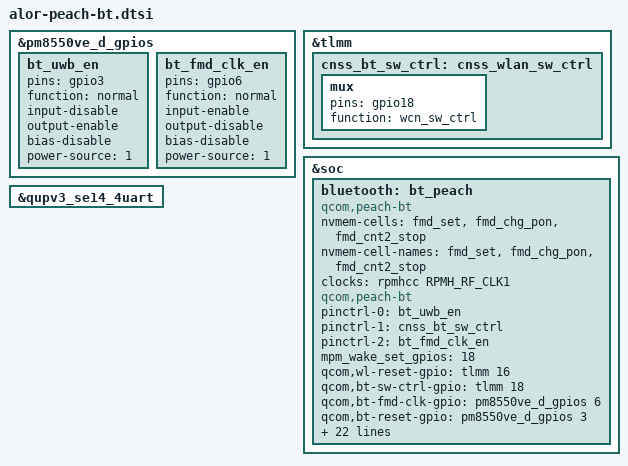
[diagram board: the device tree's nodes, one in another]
// SPDX-License-Identifier: BSD-3-Clause-Clear 
/*
 * Copyright (c) Qualcomm Technologies, Inc. and/or its subsidiaries.
 */

#include <dt-bindings/interconnect/qcom,alor.h>
#include <dt-bindings/clock/qcom,rpmh.h>

&pm8550ve_d_gpios {
	bt_uwb_en: bt_uwb_en {
		pins = "gpio3";
		function = "normal";
		input-disable;
		output-enable;
		bias-disable;
		power-source = <1>;
	};
	bt_fmd_clk_en: bt_fmd_clk_en {
		pins = "gpio6";
		function = "normal";
		input-enable;
		output-disable;
		bias-disable;
		power-source = <1>;
	};
};

&tlmm {
	cnss_bt_sw_ctrl: cnss_wlan_sw_ctrl {
		mux {
			pins = "gpio18";
			function = "wcn_sw_ctrl";
		};
	};
};

&soc {
	bluetooth: bt_peach {
		compatible = "qcom,peach-bt";
		nvmem-cells = <&fmd_set>, <&fmd_chg_pon>, <&fmd_cnt2_stop>;
		nvmem-cell-names = "fmd_set", "fmd_chg_pon", "fmd_cnt2_stop";
		clocks = <&rpmhcc RPMH_RF_CLK1>;
		clock-names = "bt_rf_clk1";
		qcom,peach-bt;
		pinctrl-names = "bt_uwb_en", "sw_ctrl", "bt_fmd_clk_en";
		pinctrl-0 = <&bt_uwb_en>;
		pinctrl-1 = <&cnss_bt_sw_ctrl>;
		pinctrl-2 = <&bt_fmd_clk_en>;
		/* List of GPIOs to be setup for interrupt wakeup capable*/
		mpm_wake_set_gpios = <18>;
		qcom,wl-reset-gpio = <&tlmm 16 0>; /* WL_EN */
		qcom,bt-sw-ctrl-gpio = <&tlmm 18 0>; /* SW_CTRL */
		qcom,bt-fmd-clk-gpio = <&pm8550ve_d_gpios 6 0>; /* FMD_CLK_CTRL */
		qcom,bt-reset-gpio = <&pm8550ve_d_gpios 3 0>; /* BT_EN */
		qcom,qmp = <&aoss_qmp>;

		qcom,bt-vdd18-aon-supply  = <&L2D>;   /* VDD1P8_AON */
		qcom,bt-vdd12-io-supply   = <&L3D>;   /* VDD1P2_IO */
		qcom,bt-ant-ldo-supply    = <&L6K>;   /* AV91C_VDD Extractor */
		qcom,bt-vdd-dig-supply    = <&S1L>;   /* BT CX_MX LDO */
		qcom,bt-vdd-aon-supply    = <&S1L>;   /* RFA_CMN/AON */
		qcom,bt-vdd-rfa0p75-supply = <&S1J>;  /* RFA_OP75 */
		qcom,bt-vdd-rfa1p8-supply  = <&S4D>;  /* RFA_1P8 */
		qcom,bt-vdd-rfa1p25-supply = <&S4F>; /* RFA_1P2 */

		qcom,bt-vdd18-aon-config  = <1800000 2000000 30000 1 1>;
		qcom,bt-vdd12-io-config   = <1200000 1200000 30000 1 1>;
		qcom,bt-ant-ldo-config    = <1800000 2000000 0 1 0>;
		qcom,bt-vdd-aon-config    = <892000 1352000 0 1 0>;
		qcom,bt-vdd-dig-config    = <892000 1352000 0 1 1>;
		qcom,bt-vdd-rfa0p75-config = <892000 1352000 0 1 0>;
		qcom,bt-vdd-rfa1p8-config = <1876000 2100000 0 1 0>;
		qcom,bt-vdd-rfa1p25-config  = <1328000 1400000 0 1 0>;

		/* WLAN CX regulator for FMD feature */
		//qcom,bt-vdd-wlan-aon-supply = <&S3D>;
		//qcom,bt-vdd-wlan-aon-config = <892000 1000000 0 0 1>;
	};
};

//uart instance
&qupv3_se14_4uart {
	status = "ok";
};
